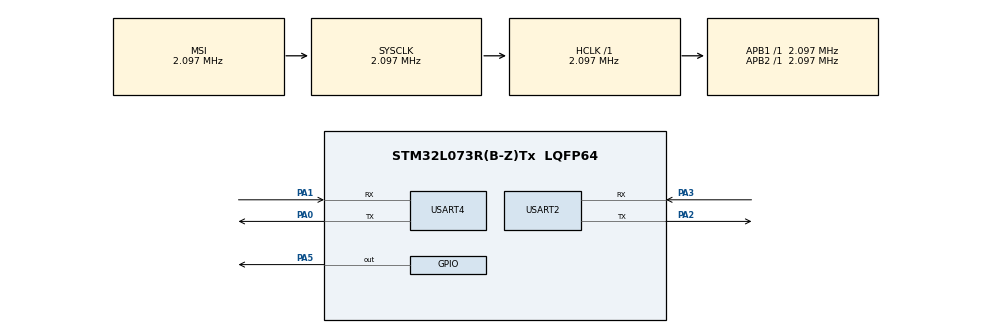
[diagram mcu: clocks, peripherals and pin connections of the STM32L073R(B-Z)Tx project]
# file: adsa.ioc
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Mcu.Family=STM32L0
Mcu.Name=STM32L073R(B-Z)Tx
Mcu.Package=LQFP64
PA0.Mode=Asynchronous
PA0.Signal=USART4_TX
PA1.Mode=Asynchronous
PA1.Signal=USART4_RX
PA2.Mode=Asynchronous
PA2.Signal=USART2_TX
PA3.Mode=Asynchronous
PA3.Signal=USART2_RX
PA5.Signal=GPIO_Output
ProjectManager.HeapSize=0x200
ProjectManager.StackSize=0x400
ProjectManager.TargetToolchain=STM32CubeIDE
RCC.AHBFreq_Value=2097000
RCC.APB1Freq_Value=2097000
RCC.APB1TimFreq_Value=2097000
RCC.APB2Freq_Value=2097000
RCC.APB2TimFreq_Value=2097000
RCC.HSE_VALUE=8000000
RCC.HSI16_VALUE=16000000
RCC.HSI48_VALUE=48000000
RCC.HSI_VALUE=16000000
RCC.LSE_VALUE=32768
RCC.MSI_VALUE=2097000
RCC.SYSCLKFreq_VALUE=2097000
RCC.VCOOutputFreq_Value=48000000
USART2.VirtualMode-Asynchronous=VM_ASYNC
USART4.VirtualMode-Asynchronous=VM_ASYNC
board=custom

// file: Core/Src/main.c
/* USER CODE BEGIN Header */
/**
  ******************************************************************************
  * @file           : main.c
  * @brief          : Main program body
  ******************************************************************************
  * @attention
  *
  * Copyright (c) 2023 STMicroelectronics.
  * All rights reserved.
  *
  * This software is licensed under terms that can be found in the LICENSE file
  * in the root directory of this software component.
  * If no LICENSE file comes with this software, it is provided AS-IS.
  *
  ******************************************************************************
  */
/* USER CODE END Header */
#include "main.h"

UART_HandleTypeDef huart2;
UART_HandleTypeDef huart4;

void SystemClock_Config(void);
static void MX_GPIO_Init(void);
static void MX_USART2_UART_Init(void);
static void MX_USART4_UART_Init(void);

int main(void)
{

  /* MCU Configuration--------------------------------------------------------*/

  /* Reset of all peripherals, Initializes the Flash interface and the Systick. */
  HAL_Init();

  /* Configure the system clock */
  SystemClock_Config();

  /* Initialize all configured peripherals */
  MX_GPIO_Init();
  MX_USART2_UART_Init();
  MX_USART4_UART_Init();

  /* Infinite loop */
  /* USER CODE BEGIN WHILE */
  while (1)
  {
	  const char message[] = "Hello world!\r\n";
	   HAL_UART_Transmit(&huart4, (uint8_t*)message, strlen(message), HAL_MAX_DELAY);

    /* USER CODE END WHILE */

  }
}

void SystemClock_Config(void)
{
  RCC_OscInitTypeDef RCC_OscInitStruct = {0};
  RCC_ClkInitTypeDef RCC_ClkInitStruct = {0};
  RCC_PeriphCLKInitTypeDef PeriphClkInit = {0};

  /** Configure the main internal regulator output voltage
  */
  __HAL_PWR_VOLTAGESCALING_CONFIG(PWR_REGULATOR_VOLTAGE_SCALE1);

  /** Initializes the RCC Oscillators according to the specified parameters
  * in the RCC_OscInitTypeDef structure.
  */
  RCC_OscInitStruct.OscillatorType = RCC_OSCILLATORTYPE_MSI;
  RCC_OscInitStruct.MSIState = RCC_MSI_ON;
  RCC_OscInitStruct.MSICalibrationValue = 0;
  RCC_OscInitStruct.MSIClockRange = RCC_MSIRANGE_5;
  RCC_OscInitStruct.PLL.PLLState = RCC_PLL_NONE;
  if (HAL_RCC_OscConfig(&RCC_OscInitStruct) != HAL_OK)
  {
    Error_Handler();
  }

  /** Initializes the CPU, AHB and APB buses clocks
  */
  RCC_ClkInitStruct.ClockType = RCC_CLOCKTYPE_HCLK|RCC_CLOCKTYPE_SYSCLK
                              |RCC_CLOCKTYPE_PCLK1|RCC_CLOCKTYPE_PCLK2;
  RCC_ClkInitStruct.SYSCLKSource = RCC_SYSCLKSOURCE_MSI;
  RCC_ClkInitStruct.AHBCLKDivider = RCC_SYSCLK_DIV1;
  RCC_ClkInitStruct.APB1CLKDivider = RCC_HCLK_DIV1;
  RCC_ClkInitStruct.APB2CLKDivider = RCC_HCLK_DIV1;

  if (HAL_RCC_ClockConfig(&RCC_ClkInitStruct, FLASH_LATENCY_0) != HAL_OK)
  {
    Error_Handler();
  }
  PeriphClkInit.PeriphClockSelection = RCC_PERIPHCLK_USART2;
  PeriphClkInit.Usart2ClockSelection = RCC_USART2CLKSOURCE_PCLK1;
  if (HAL_RCCEx_PeriphCLKConfig(&PeriphClkInit) != HAL_OK)
  {
    Error_Handler();
  }
}

static void MX_USART2_UART_Init(void)
{

  huart2.Instance = USART2;
  huart2.Init.BaudRate = 115200;
  huart2.Init.WordLength = UART_WORDLENGTH_8B;
  huart2.Init.StopBits = UART_STOPBITS_1;
  huart2.Init.Parity = UART_PARITY_NONE;
  huart2.Init.Mode = UART_MODE_TX_RX;
  huart2.Init.HwFlowCtl = UART_HWCONTROL_NONE;
  huart2.Init.OverSampling = UART_OVERSAMPLING_16;
  huart2.Init.OneBitSampling = UART_ONE_BIT_SAMPLE_DISABLE;
  huart2.AdvancedInit.AdvFeatureInit = UART_ADVFEATURE_NO_INIT;
  if (HAL_UART_Init(&huart2) != HAL_OK)
  {
    Error_Handler();
  }

}

static void MX_USART4_UART_Init(void)
{

  huart4.Instance = USART4;
  huart4.Init.BaudRate = 115200;
  huart4.Init.WordLength = UART_WORDLENGTH_8B;
  huart4.Init.StopBits = UART_STOPBITS_1;
  huart4.Init.Parity = UART_PARITY_NONE;
  huart4.Init.Mode = UART_MODE_TX_RX;
  huart4.Init.HwFlowCtl = UART_HWCONTROL_NONE;
  huart4.Init.OverSampling = UART_OVERSAMPLING_16;
  huart4.Init.OneBitSampling = UART_ONE_BIT_SAMPLE_DISABLE;
  huart4.AdvancedInit.AdvFeatureInit = UART_ADVFEATURE_NO_INIT;
  if (HAL_UART_Init(&huart4) != HAL_OK)
  {
    Error_Handler();
  }

}

static void MX_GPIO_Init(void)
{

  /* GPIO Ports Clock Enable */
  __HAL_RCC_GPIOA_CLK_ENABLE();

}

void Error_Handler(void)
{
  __disable_irq();
  while (1)
  {
  }
}
